# ESP32-C5 register map
Vendor: ESPRESSIF SYSTEMS (SHANGHAI) CO., LTD.; Series: ESP32 C-Series; File version: 1
CPU: RV32IMAC r0p0, little endian, no MPU, no FPU, 0 interrupt priority bits
Address unit: 32 bits
Registers are 32-bit, read-write, reset 0x0 unless marked. A register's access mark holds for its fields unless they carry their own. Offsets are from the block's base; [hi:lo] are bit positions; {n}, {i} and the like mark numbered series.

## HMAC — HMAC (Hash-based Message Authentication Code) Accelerator
Base 0x6008D000
0x40 SET_START wo — Process control register 0.
  [0] SET_START — Start hmac operation.
0x44 SET_PARA_PURPOSE wo — Configure purpose.
  [3:0] PURPOSE_SET — Set hmac parameter purpose.
0x48 SET_PARA_KEY wo — Configure key.
  [2:0] KEY_SET — Set hmac parameter key.
0x4C SET_PARA_FINISH wo — Finish initial configuration.
  [0] SET_PARA_END — Finish hmac configuration.
0x50 SET_MESSAGE_ONE wo — Process control register 1.
  [0] SET_TEXT_ONE — Call SHA to calculate one message block.
0x54 SET_MESSAGE_ING wo — Process control register 2.
  [0] SET_TEXT_ING — Continue typical hmac.
0x58 SET_MESSAGE_END wo — Process control register 3.
  [0] SET_TEXT_END — Start hardware padding.
0x5C SET_RESULT_FINISH wo — Process control register 4.
  [0] SET_RESULT_END — After read result from upstream, then let hmac back to idle.
0x60 SET_INVALIDATE_JTAG wo — Invalidate register 0.
  [0] SET_INVALIDATE_JTAG — Clear result from hmac downstream JTAG.
0x64 SET_INVALIDATE_DS wo — Invalidate register 1.
  [0] SET_INVALIDATE_DS — Clear result from hmac downstream DS.
0x68 QUERY_ERROR ro — Error register.
  [0] QUERY_CHECK — Hmac configuration state. 0: key are agree with purpose. 1: error
0x6C QUERY_BUSY ro — Busy register.
  [0] BUSY_STATE — Hmac state. 1'b0: idle. 1'b1: busy
{0x80+i} WR_MESSAGE_MEM[{i}] (i=0..63) 8-bit access not given — Message block memory.
{0xC0+i} RD_RESULT_MEM[{i}] (i=0..31) 8-bit access not given — Result from upstream.
0xF0 SET_MESSAGE_PAD wo — Process control register 5.
  [0] SET_TEXT_PAD — Start software padding.
0xF4 ONE_BLOCK wo — Process control register 6.
  [0] SET_ONE_BLOCK — Don't have to do padding.
0xF8 SOFT_JTAG_CTRL wo — Jtag register 0.
  [0] SOFT_JTAG_CTRL — Turn on JTAG verification.
0xFC WR_JTAG wo — Jtag register 1.
  [31:0] WR_JTAG — 32-bit of key to be compared.
0x1FC DATE reset 0x20200618
  [29:0] DATE — Hmac date information/ hmac version information.

## HP_APM — HP_APM Peripheral
Base 0x60099000
0x00 REGION_FILTER_EN reset 0x1 — Region filter enable register
  [15:0] REGION_FILTER_EN — Configure bit 0 (0-15) to enable region 0.\\ 0: disable \\ 1: enable \\
{0x4+0xC*i} REGION{i}_ADDR_START (i=0..15) — Region address register
  [31:0] REGION_ADDR_START — Configures start address of region %s.
{0x8+0xC*i} REGION{i}_ADDR_END (i=0..15) reset 0xFFFFFFFF — Region address register
  [31:0] REGION_ADDR_END — Configures end address of region %s.
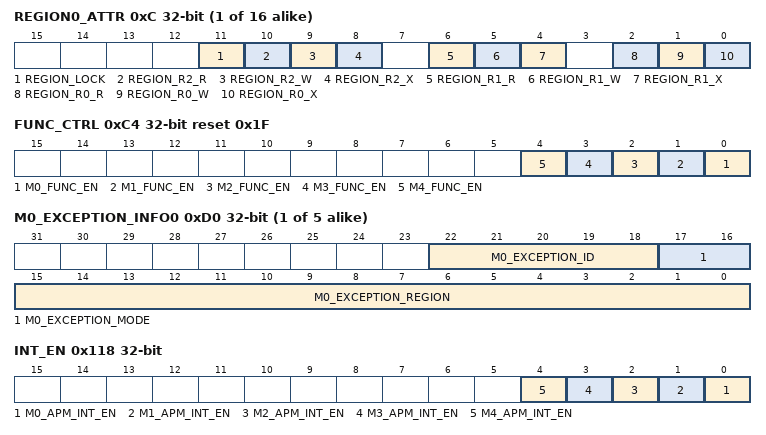
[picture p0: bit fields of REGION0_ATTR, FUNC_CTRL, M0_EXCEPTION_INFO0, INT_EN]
{0xC+0xC*i} REGION{i}_ATTR (i=0..15) — Region access authority attribute register
  [11] REGION_LOCK — Set 1 to lock region0 configuration
  [10] REGION_R2_R — Configures the read authority of REE_MODE 2 in region %s.
  [9] REGION_R2_W — Configures the write authority of REE_MODE 2 in region %s.
  [8] REGION_R2_X — Configures the execution authority of REE_MODE 2 in region %s.
  [6] REGION_R1_R — Configures the read authority of REE_MODE 1 in region %s.
  [5] REGION_R1_W — Configures the write authority of REE_MODE 1 in region %s.
  [4] REGION_R1_X — Configures the execution authority of REE_MODE 1 in region %s.
  [2] REGION_R0_R — Configures the read authority of REE_MODE 0 in region %s.
  [1] REGION_R0_W — Configures the write authority of REE_MODE 0 in region %s.
  [0] REGION_R0_X — Configures the execution authority of REE_MODE 0 in region %s.
0xC4 FUNC_CTRL reset 0x1F — APM function control register
  [n] M{n}_FUNC_EN (n=0..4) — PMS M{n} function enable
{0xC8+0x10*i} M{i}_STATUS ro (i=0..4)
  [1:0] M{i}_EXCEPTION_STATUS — Represents exception status.\\ bit0: 1 represents authority_exception \\ bit1: 1 represents space_exception \\
{0xCC+0x10*i} M{i}_STATUS_CLR wo (i=0..4) — M{i} status clear register
  [0] M{i}_EXCEPTION_STATUS_CLR — Configures to clear exception status.
{0xD0+0x10*i} M{i}_EXCEPTION_INFO0 ro (i=0..4)
  [22:18] M{i}_EXCEPTION_ID — Represents exception id information.
  [17:16] M{i}_EXCEPTION_MODE — Represents exception mode.
  [15:0] M{i}_EXCEPTION_REGION — Represents exception region.
{0xD4+0x10*i} M{i}_EXCEPTION_INFO1 ro (i=0..4)
  [31:0] M{i}_EXCEPTION_ADDR — Represents exception addr.
0x118 INT_EN — APM interrupt enable register
  [n] M{n}_APM_INT_EN (n=0..4) — Configures to enable APM M{n} interrupt.\\ 0: disable \\ 1: enable \\
0x7F8 CLOCK_GATE reset 0x1 — Clock gating register
  [0] CLK_EN — Configures whether to keep the clock always on.\\ 0: enable automatic clock gating \\ 1: keep the clock always on \\
0x7FC DATE reset 0x2312010 — Version control register
  [27:0] DATE — Version control register.
